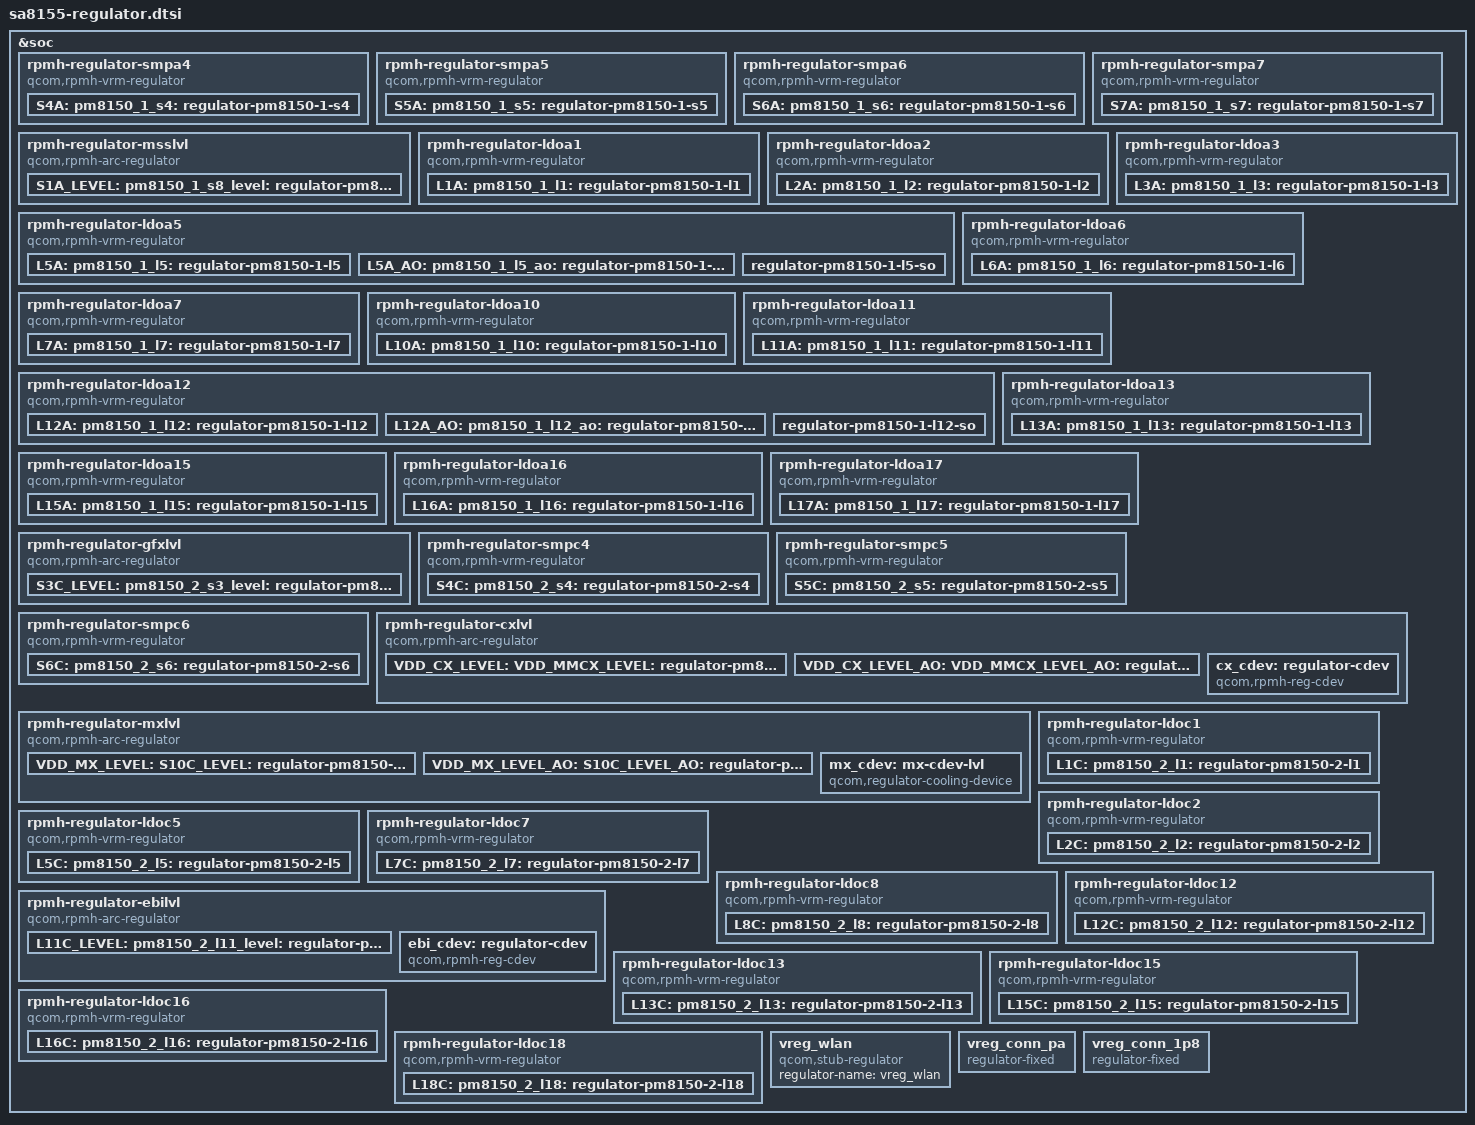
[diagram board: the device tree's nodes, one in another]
/* Copyright (c) 2018, The Linux Foundation. All rights reserved.
 *
 * This program is free software; you can redistribute it and/or modify
 * it under the terms of the GNU General Public License version 2 and
 * only version 2 as published by the Free Software Foundation.
 *
 * This program is distributed in the hope that it will be useful,
 * but WITHOUT ANY WARRANTY; without even the implied warranty of
 * MERCHANTABILITY or FITNESS FOR A PARTICULAR PURPOSE.  See the
 * GNU General Public License for more details.
 */

#include <dt-bindings/regulator/qcom,rpmh-regulator.h>

&soc {
	/* RPMh regulators: */

	rpmh-regulator-smpa4 {
		compatible = "qcom,rpmh-vrm-regulator";
		mboxes = <&apps_rsc 0>;
		qcom,resource-name = "smpa4";
		S4A: pm8150_1_s4: regulator-pm8150-1-s4 {
			regulator-name = "pm8150_1_s4";
			qcom,set = <RPMH_REGULATOR_SET_ALL>;
			regulator-min-microvolt = <1800000>;
			regulator-max-microvolt = <1800000>;
			qcom,init-voltage = <1800000>;
		};
	};

	rpmh-regulator-smpa5 {
		compatible = "qcom,rpmh-vrm-regulator";
		mboxes = <&apps_rsc 0>;
		qcom,resource-name = "smpa5";
		S5A: pm8150_1_s5: regulator-pm8150-1-s5 {
			regulator-name = "pm8150_1_s5";
			qcom,set = <RPMH_REGULATOR_SET_ALL>;
			regulator-min-microvolt = <1824000>;
			regulator-max-microvolt = <2040000>;
			qcom,init-voltage = <1824000>;
		};
	};

	rpmh-regulator-smpa6 {
		compatible = "qcom,rpmh-vrm-regulator";
		mboxes = <&apps_rsc 0>;
		qcom,resource-name = "smpa6";
		S6A: pm8150_1_s6: regulator-pm8150-1-s6 {
			regulator-name = "pm8150_1_s6";
			qcom,set = <RPMH_REGULATOR_SET_ALL>;
			regulator-min-microvolt = <600000>;
			regulator-max-microvolt = <1352000>;
			qcom,init-voltage = <600000>;
		};
	};

	rpmh-regulator-smpa7 {
		compatible = "qcom,rpmh-vrm-regulator";
		mboxes = <&apps_rsc 0>;
		qcom,resource-name = "smpa7";
		S7A: pm8150_1_s7: regulator-pm8150-1-s7 {
			regulator-name = "pm8150_1_s7";
			qcom,set = <RPMH_REGULATOR_SET_ALL>;
			regulator-min-microvolt = <600000>;
			regulator-max-microvolt = <600000>;
			qcom,init-voltage = <600000>;
		};
	};

	/* PM8150_1 S8 = VDD_MODEM supply */
	rpmh-regulator-msslvl {
		compatible = "qcom,rpmh-arc-regulator";
		mboxes = <&apps_rsc 0>;
		qcom,resource-name = "mss.lvl";
		S1A_LEVEL: pm8150_1_s8_level: regulator-pm8150-1-s8-level {
			regulator-name = "pm8150_1_s8_level";
			qcom,set = <RPMH_REGULATOR_SET_ALL>;
			regulator-min-microvolt
				= <RPMH_REGULATOR_LEVEL_RETENTION>;
			regulator-max-microvolt
				= <RPMH_REGULATOR_LEVEL_MAX>;
			qcom,init-voltage-level
				= <RPMH_REGULATOR_LEVEL_RETENTION>;
		};
	};

	rpmh-regulator-ldoa1 {
		compatible = "qcom,rpmh-vrm-regulator";
		mboxes = <&apps_rsc 0>;
		qcom,resource-name = "ldoa1";
		qcom,regulator-type = "pmic5-ldo";
		qcom,supported-modes =
			<RPMH_REGULATOR_MODE_LPM
			 RPMH_REGULATOR_MODE_HPM>;
		qcom,mode-threshold-currents = <0 1>;
		L1A: pm8150_1_l1: regulator-pm8150-1-l1 {
			regulator-name = "pm8150_1_l1";
			qcom,set = <RPMH_REGULATOR_SET_ALL>;
			regulator-min-microvolt = <752000>;
			regulator-max-microvolt = <752000>;
			qcom,init-voltage = <752000>;
			qcom,init-mode = <RPMH_REGULATOR_MODE_LPM>;
		};
	};

	rpmh-regulator-ldoa2 {
		compatible = "qcom,rpmh-vrm-regulator";
		mboxes = <&apps_rsc 0>;
		qcom,resource-name = "ldoa2";
		qcom,regulator-type = "pmic5-ldo";
		qcom,supported-modes =
			<RPMH_REGULATOR_MODE_LPM
			 RPMH_REGULATOR_MODE_HPM>;
		qcom,mode-threshold-currents = <0 10000>;
		L2A: pm8150_1_l2: regulator-pm8150-1-l2 {
			regulator-name = "pm8150_1_l2";
			qcom,set = <RPMH_REGULATOR_SET_ALL>;
			regulator-min-microvolt = <3072000>;
			regulator-max-microvolt = <3072000>;
			qcom,init-voltage = <3072000>;
			qcom,init-mode = <RPMH_REGULATOR_MODE_LPM>;
		};
	};

	rpmh-regulator-ldoa3 {
		compatible = "qcom,rpmh-vrm-regulator";
		mboxes = <&apps_rsc 0>;
		qcom,resource-name = "ldoa3";
		qcom,regulator-type = "pmic5-ldo";
		qcom,supported-modes =
			<RPMH_REGULATOR_MODE_LPM
			 RPMH_REGULATOR_MODE_HPM>;
		qcom,mode-threshold-currents = <0 1>;
		L3A: pm8150_1_l3: regulator-pm8150-1-l3 {
			regulator-name = "pm8150_1_l3";
			qcom,set = <RPMH_REGULATOR_SET_ALL>;
			regulator-min-microvolt = <480000>;
			regulator-max-microvolt = <932000>;
			qcom,init-voltage = <480000>;
			qcom,init-mode = <RPMH_REGULATOR_MODE_LPM>;
		};
	};

	rpmh-regulator-ldoa5 {
		compatible = "qcom,rpmh-vrm-regulator";
		mboxes = <&apps_rsc 0>;
		qcom,resource-name = "ldoa5";
		qcom,regulator-type = "pmic5-ldo";
		qcom,supported-modes =
			<RPMH_REGULATOR_MODE_LPM
			 RPMH_REGULATOR_MODE_HPM>;
		qcom,mode-threshold-currents = <0 1>;

		L5A: pm8150_1_l5: regulator-pm8150-1-l5 {
			regulator-name = "pm8150_1_l5";
			qcom,set = <RPMH_REGULATOR_SET_ALL>;
			regulator-min-microvolt = <880000>;
			regulator-max-microvolt = <888000>;
			qcom,init-voltage = <880000>;
			qcom,init-mode = <RPMH_REGULATOR_MODE_LPM>;
		};

		L5A_AO: pm8150_1_l5_ao: regulator-pm8150-1-l5-ao {
			regulator-name = "pm8150_1_l5_ao";
			qcom,set = <RPMH_REGULATOR_SET_ACTIVE>;
			regulator-min-microvolt = <880000>;
			regulator-max-microvolt = <888000>;
			qcom,init-voltage = <880000>;
			qcom,init-mode = <RPMH_REGULATOR_MODE_LPM>;
		};

		regulator-pm8150-1-l5-so {
			regulator-name = "pm8150_1_l5_so";
			qcom,set = <RPMH_REGULATOR_SET_SLEEP>;
			regulator-min-microvolt = <880000>;
			regulator-max-microvolt = <888000>;
			qcom,init-voltage = <880000>;
			qcom,init-mode = <RPMH_REGULATOR_MODE_LPM>;
			qcom,init-enable = <0>;
		};
	};

	rpmh-regulator-ldoa6 {
		compatible = "qcom,rpmh-vrm-regulator";
		mboxes = <&apps_rsc 0>;
		qcom,resource-name = "ldoa6";
		qcom,regulator-type = "pmic5-ldo";
		qcom,supported-modes =
			<RPMH_REGULATOR_MODE_LPM
			 RPMH_REGULATOR_MODE_HPM>;
		qcom,mode-threshold-currents = <0 10000>;
		L6A: pm8150_1_l6: regulator-pm8150-1-l6 {
			regulator-name = "pm8150_1_l6";
			qcom,set = <RPMH_REGULATOR_SET_ALL>;
			regulator-min-microvolt = <1200000>;
			regulator-max-microvolt = <1200000>;
			qcom,init-voltage = <1200000>;
			qcom,init-mode = <RPMH_REGULATOR_MODE_LPM>;
		};
	};

	rpmh-regulator-ldoa7 {
		compatible = "qcom,rpmh-vrm-regulator";
		mboxes = <&apps_rsc 0>;
		qcom,resource-name = "ldoa7";
		qcom,regulator-type = "pmic5-ldo";
		qcom,supported-modes =
			<RPMH_REGULATOR_MODE_LPM
			 RPMH_REGULATOR_MODE_HPM>;
		qcom,mode-threshold-currents = <0 1>;
		L7A: pm8150_1_l7: regulator-pm8150-1-l7 {
			regulator-name = "pm8150_1_l7";
			qcom,set = <RPMH_REGULATOR_SET_ALL>;
			regulator-min-microvolt = <1800000>;
			regulator-max-microvolt = <1800000>;
			qcom,init-voltage = <1800000>;
			qcom,init-mode = <RPMH_REGULATOR_MODE_LPM>;
		};
	};

	rpmh-regulator-ldoa10 {
		compatible = "qcom,rpmh-vrm-regulator";
		mboxes = <&apps_rsc 0>;
		qcom,resource-name = "ldoa10";
		qcom,regulator-type = "pmic5-ldo";
		qcom,supported-modes =
			<RPMH_REGULATOR_MODE_LPM
			 RPMH_REGULATOR_MODE_HPM>;
		qcom,mode-threshold-currents = <0 10000>;
		L10A: pm8150_1_l10: regulator-pm8150-1-l10 {
			regulator-name = "pm8150_1_l10";
			qcom,set = <RPMH_REGULATOR_SET_ALL>;
			regulator-min-microvolt = <2504000>;
			regulator-max-microvolt = <2960000>;
			qcom,init-voltage = <2504000>;
			qcom,init-mode = <RPMH_REGULATOR_MODE_LPM>;
		};
	};

	rpmh-regulator-ldoa11 {
		compatible = "qcom,rpmh-vrm-regulator";
		mboxes = <&apps_rsc 0>;
		qcom,resource-name = "ldoa11";
		qcom,regulator-type = "pmic5-ldo";
		qcom,supported-modes =
			<RPMH_REGULATOR_MODE_LPM
			 RPMH_REGULATOR_MODE_HPM>;
		qcom,mode-threshold-currents = <0 1>;
		L11A: pm8150_1_l11: regulator-pm8150-1-l11 {
			regulator-name = "pm8150_1_l11";
			qcom,set = <RPMH_REGULATOR_SET_ALL>;
			regulator-min-microvolt = <800000>;
			regulator-max-microvolt = <800000>;
			qcom,init-voltage = <800000>;
			qcom,init-mode = <RPMH_REGULATOR_MODE_LPM>;
		};
	};

	rpmh-regulator-ldoa12 {
		compatible = "qcom,rpmh-vrm-regulator";
		mboxes = <&apps_rsc 0>;
		qcom,resource-name = "ldoa12";
		qcom,regulator-type = "pmic5-ldo";
		qcom,supported-modes =
			<RPMH_REGULATOR_MODE_LPM
			 RPMH_REGULATOR_MODE_HPM>;
		qcom,mode-threshold-currents = <0 1>;
		L12A: pm8150_1_l12: regulator-pm8150-1-l12 {
			regulator-name = "pm8150_1_l12";
			qcom,set = <RPMH_REGULATOR_SET_ALL>;
			regulator-min-microvolt = <1800000>;
			regulator-max-microvolt = <1800000>;
			qcom,init-voltage = <1800000>;
			qcom,init-mode = <RPMH_REGULATOR_MODE_LPM>;
		};

		L12A_AO: pm8150_1_l12_ao: regulator-pm8150-1-l12-ao {
			regulator-name = "pm8150_1_l12_ao";
			qcom,set = <RPMH_REGULATOR_SET_ACTIVE>;
			regulator-min-microvolt = <1800000>;
			regulator-max-microvolt = <1800000>;
			qcom,init-voltage = <1800000>;
			qcom,init-mode = <RPMH_REGULATOR_MODE_LPM>;
		};

		regulator-pm8150-1-l12-so {
			regulator-name = "pm8150_1_l12_so";
			qcom,set = <RPMH_REGULATOR_SET_SLEEP>;
			regulator-min-microvolt = <1800000>;
			regulator-max-microvolt = <1800000>;
			qcom,init-voltage = <1800000>;
			qcom,init-mode = <RPMH_REGULATOR_MODE_LPM>;
			qcom,init-enable = <0>;
		};
	};

	rpmh-regulator-ldoa13 {
		compatible = "qcom,rpmh-vrm-regulator";
		mboxes = <&apps_rsc 0>;
		qcom,resource-name = "ldoa13";
		qcom,regulator-type = "pmic5-ldo";
		qcom,supported-modes =
			<RPMH_REGULATOR_MODE_LPM
			 RPMH_REGULATOR_MODE_HPM>;
		qcom,mode-threshold-currents = <0 1>;
		L13A: pm8150_1_l13: regulator-pm8150-1-l13 {
			regulator-name = "pm8150_1_l13";
			qcom,set = <RPMH_REGULATOR_SET_ALL>;
			regulator-min-microvolt = <2704000>;
			regulator-max-microvolt = <2704000>;
			qcom,init-voltage = <2704000>;
			qcom,init-mode = <RPMH_REGULATOR_MODE_LPM>;
		};
	};

	rpmh-regulator-ldoa15 {
		compatible = "qcom,rpmh-vrm-regulator";
		mboxes = <&apps_rsc 0>;
		qcom,resource-name = "ldoa15";
		qcom,regulator-type = "pmic5-ldo";
		qcom,supported-modes =
			<RPMH_REGULATOR_MODE_LPM
			 RPMH_REGULATOR_MODE_HPM>;
		qcom,mode-threshold-currents = <0 1>;
		L15A: pm8150_1_l15: regulator-pm8150-1-l15 {
			regulator-name = "pm8150_1_l15";
			qcom,set = <RPMH_REGULATOR_SET_ALL>;
			regulator-min-microvolt = <1704000>;
			regulator-max-microvolt = <1704000>;
			qcom,init-voltage = <1704000>;
			qcom,init-mode = <RPMH_REGULATOR_MODE_LPM>;
		};
	};

	rpmh-regulator-ldoa16 {
		compatible = "qcom,rpmh-vrm-regulator";
		mboxes = <&apps_rsc 0>;
		qcom,resource-name = "ldoa16";
		qcom,regulator-type = "pmic5-ldo";
		qcom,supported-modes =
			<RPMH_REGULATOR_MODE_LPM
			 RPMH_REGULATOR_MODE_HPM>;
		qcom,mode-threshold-currents = <0 1>;
		L16A: pm8150_1_l16: regulator-pm8150-1-l16 {
			regulator-name = "pm8150_1_l16";
			qcom,set = <RPMH_REGULATOR_SET_ALL>;
			regulator-min-microvolt = <2704000>;
			regulator-max-microvolt = <2960000>;
			qcom,init-voltage = <2704000>;
			qcom,init-mode = <RPMH_REGULATOR_MODE_LPM>;
		};
	};

	rpmh-regulator-ldoa17 {
		compatible = "qcom,rpmh-vrm-regulator";
		mboxes = <&apps_rsc 0>;
		qcom,resource-name = "ldoa17";
		qcom,regulator-type = "pmic5-ldo";
		qcom,supported-modes =
			<RPMH_REGULATOR_MODE_LPM
			 RPMH_REGULATOR_MODE_HPM>;
		qcom,mode-threshold-currents = <0 1>;
		L17A: pm8150_1_l17: regulator-pm8150-1-l17 {
			regulator-name = "pm8150_1_l17";
			qcom,set = <RPMH_REGULATOR_SET_ALL>;
			regulator-min-microvolt = <2704000>;
			regulator-max-microvolt = <2960000>;
			qcom,init-voltage = <2704000>;
			qcom,init-mode = <RPMH_REGULATOR_MODE_LPM>;
		};
	};

	/* PM8150_2 S3 + S2 + S1 = 3 phase VDD_GFX supply */
	rpmh-regulator-gfxlvl {
		compatible = "qcom,rpmh-arc-regulator";
		mboxes = <&apps_rsc 0>;
		qcom,resource-name = "gfx.lvl";
		S3C_LEVEL: pm8150_2_s3_level: regulator-pm8150-2-s3-level {
			regulator-name = "pm8150_2_s3_level";
			qcom,set = <RPMH_REGULATOR_SET_ALL>;
			regulator-min-microvolt
				= <RPMH_REGULATOR_LEVEL_RETENTION>;
			regulator-max-microvolt
				= <RPMH_REGULATOR_LEVEL_MAX>;
			qcom,init-voltage-level
				= <RPMH_REGULATOR_LEVEL_RETENTION>;
		};
	};

	rpmh-regulator-smpc4 {
		compatible = "qcom,rpmh-vrm-regulator";
		mboxes = <&apps_rsc 0>;
		qcom,resource-name = "smpc4";
		S4C: pm8150_2_s4: regulator-pm8150-2-s4 {
			regulator-name = "pm8150_2_s4";
			qcom,set = <RPMH_REGULATOR_SET_ALL>;
			regulator-min-microvolt = <800000>;
			regulator-max-microvolt = <1400000>;
			qcom,init-voltage = <800000>;
		};
	};

	rpmh-regulator-smpc5 {
		compatible = "qcom,rpmh-vrm-regulator";
		mboxes = <&apps_rsc 0>;
		qcom,resource-name = "smpc5";
		S5C: pm8150_2_s5: regulator-pm8150-2-s5 {
			regulator-name = "pm8150_2_s5";
			qcom,set = <RPMH_REGULATOR_SET_ALL>;
			regulator-min-microvolt = <1824000>;
			regulator-max-microvolt = <2040000>;
			qcom,init-voltage = <1824000>;
		};
	};

	rpmh-regulator-smpc6 {
		compatible = "qcom,rpmh-vrm-regulator";
		mboxes = <&apps_rsc 0>;
		qcom,resource-name = "smpc6";
		S6C: pm8150_2_s6: regulator-pm8150-2-s6 {
			regulator-name = "pm8150_2_s6";
			qcom,set = <RPMH_REGULATOR_SET_ALL>;
			regulator-min-microvolt = <1128000>;
			regulator-max-microvolt = <1128000>;
			qcom,init-voltage = <1128000>;
		};
	};

	/* PM8150_2 S9 + S8 + S7 = VDD_CX supply */
	rpmh-regulator-cxlvl {
		compatible = "qcom,rpmh-arc-regulator";
		mboxes = <&apps_rsc 0>;
		qcom,resource-name = "cx.lvl";
		pm8150_2_s9_level-parent-supply = <&VDD_MX_LEVEL>;
		pm8150_2_s9_level_ao-parent-supply = <&VDD_MX_LEVEL_AO>;

		VDD_CX_LEVEL: VDD_MMCX_LEVEL:
		S9C_LEVEL: pm8150_2_s9_level: regulator-pm8150-2-s9-level {
			regulator-name = "pm8150_2_s9_level";
			qcom,set = <RPMH_REGULATOR_SET_ALL>;
			regulator-min-microvolt
				= <RPMH_REGULATOR_LEVEL_RETENTION>;
			regulator-max-microvolt
				= <RPMH_REGULATOR_LEVEL_MAX>;
			qcom,init-voltage-level
				= <RPMH_REGULATOR_LEVEL_RETENTION>;
			qcom,min-dropout-voltage-level = <(-1)>;
		};

		VDD_CX_LEVEL_AO: VDD_MMCX_LEVEL_AO: S9C_LEVEL_AO:
		pm8150_2_s9_level_ao: regulator-pm8150-2-s9-level-ao {
			regulator-name = "pm8150_2_s9_level_ao";
			qcom,set = <RPMH_REGULATOR_SET_ACTIVE>;
			regulator-min-microvolt
				= <RPMH_REGULATOR_LEVEL_RETENTION>;
			regulator-max-microvolt
				= <RPMH_REGULATOR_LEVEL_MAX>;
			qcom,init-voltage-level
				= <RPMH_REGULATOR_LEVEL_RETENTION>;
			qcom,min-dropout-voltage-level = <(-1)>;
		};

		cx_cdev: regulator-cdev {
			compatible = "qcom,rpmh-reg-cdev";
			mboxes = <&qmp_aop 0>;
			qcom,reg-resource-name = "cx";
			#cooling-cells = <2>;
		};
	};

	/* PM8150_2 S10 = VDD_MX supply */
	rpmh-regulator-mxlvl {
		compatible = "qcom,rpmh-arc-regulator";
		mboxes = <&apps_rsc 0>;
		qcom,resource-name = "mx.lvl";

		VDD_MX_LEVEL:
		S10C_LEVEL: pm8150_2_s10_level: regulator-pm8150-2-s10-level {
			regulator-name = "pm8150_2_s10_level";
			qcom,set = <RPMH_REGULATOR_SET_ALL>;
			regulator-min-microvolt
				= <RPMH_REGULATOR_LEVEL_RETENTION>;
			regulator-max-microvolt
				= <RPMH_REGULATOR_LEVEL_MAX>;
			qcom,init-voltage-level
				= <RPMH_REGULATOR_LEVEL_RETENTION>;
		};

		VDD_MX_LEVEL_AO: S10C_LEVEL_AO:
		pm8150_2_s10_level_ao: regulator-pm8150-2-s10-level-ao {
			regulator-name = "pm8150_2_s10_level_ao";
			qcom,set = <RPMH_REGULATOR_SET_ACTIVE>;
			regulator-min-microvolt
				= <RPMH_REGULATOR_LEVEL_RETENTION>;
			regulator-max-microvolt
				= <RPMH_REGULATOR_LEVEL_MAX>;
			qcom,init-voltage-level
				= <RPMH_REGULATOR_LEVEL_RETENTION>;
		};

		mx_cdev: mx-cdev-lvl {
			compatible = "qcom,regulator-cooling-device";
			regulator-cdev-supply = <&VDD_MX_LEVEL>;
			regulator-levels = <RPMH_REGULATOR_LEVEL_NOM
					RPMH_REGULATOR_LEVEL_OFF>;
			#cooling-cells = <2>;
		};
	};

	rpmh-regulator-ldoc1 {
		compatible = "qcom,rpmh-vrm-regulator";
		mboxes = <&apps_rsc 0>;
		qcom,resource-name = "ldoc1";
		qcom,regulator-type = "pmic5-ldo";
		qcom,supported-modes =
			<RPMH_REGULATOR_MODE_LPM
			 RPMH_REGULATOR_MODE_HPM>;
		qcom,mode-threshold-currents = <0 1>;
		L1C: pm8150_2_l1: regulator-pm8150-2-l1 {
			regulator-name = "pm8150_2_l1";
			qcom,set = <RPMH_REGULATOR_SET_ALL>;
			regulator-min-microvolt = <1304000>;
			regulator-max-microvolt = <1304000>;
			qcom,init-voltage = <1304000>;
			qcom,init-mode = <RPMH_REGULATOR_MODE_LPM>;
		};
	};

	rpmh-regulator-ldoc2 {
		compatible = "qcom,rpmh-vrm-regulator";
		mboxes = <&apps_rsc 0>;
		qcom,resource-name = "ldoc2";
		qcom,regulator-type = "pmic5-ldo";
		qcom,supported-modes =
			<RPMH_REGULATOR_MODE_LPM
			 RPMH_REGULATOR_MODE_HPM>;
		qcom,mode-threshold-currents = <0 1>;
		L2C: pm8150_2_l2: regulator-pm8150-2-l2 {
			regulator-name = "pm8150_2_l2";
			qcom,set = <RPMH_REGULATOR_SET_ALL>;
			regulator-min-microvolt = <1704000>;
			regulator-max-microvolt = <2928000>;
			qcom,init-voltage = <1704000>;
			qcom,init-mode = <RPMH_REGULATOR_MODE_LPM>;
		};
	};

	rpmh-regulator-ldoc5 {
		compatible = "qcom,rpmh-vrm-regulator";
		mboxes = <&apps_rsc 0>;
		qcom,resource-name = "ldoc5";
		qcom,regulator-type = "pmic5-ldo";
		qcom,supported-modes =
			<RPMH_REGULATOR_MODE_LPM
			 RPMH_REGULATOR_MODE_HPM>;
		qcom,mode-threshold-currents = <0 1>;
		L5C: pm8150_2_l5: regulator-pm8150-2-l5 {
			regulator-name = "pm8150_2_l5";
			qcom,set = <RPMH_REGULATOR_SET_ALL>;
			regulator-min-microvolt = <1200000>;
			regulator-max-microvolt = <1200000>;
			qcom,init-voltage = <1200000>;
			qcom,init-mode = <RPMH_REGULATOR_MODE_LPM>;
		};
	};

	rpmh-regulator-ldoc7 {
		compatible = "qcom,rpmh-vrm-regulator";
		mboxes = <&apps_rsc 0>;
		qcom,resource-name = "ldoc7";
		qcom,regulator-type = "pmic5-ldo";
		qcom,supported-modes =
			<RPMH_REGULATOR_MODE_LPM
			 RPMH_REGULATOR_MODE_HPM>;
		qcom,mode-threshold-currents = <0 1>;
		L7C: pm8150_2_l7: regulator-pm8150-2-l7 {
			regulator-name = "pm8150_2_l7";
			qcom,set = <RPMH_REGULATOR_SET_ALL>;
			regulator-min-microvolt = <1800000>;
			regulator-max-microvolt = <1800000>;
			qcom,init-voltage = <1800000>;
			qcom,init-mode = <RPMH_REGULATOR_MODE_LPM>;
		};
	};

	rpmh-regulator-ldoc8 {
		compatible = "qcom,rpmh-vrm-regulator";
		mboxes = <&apps_rsc 0>;
		qcom,resource-name = "ldoc8";
		qcom,regulator-type = "pmic5-ldo";
		qcom,supported-modes =
			<RPMH_REGULATOR_MODE_LPM
			 RPMH_REGULATOR_MODE_HPM>;
		qcom,mode-threshold-currents = <0 1>;
		L8C: pm8150_2_l8: regulator-pm8150-2-l8 {
			regulator-name = "pm8150_2_l8";
			qcom,set = <RPMH_REGULATOR_SET_ALL>;
			regulator-min-microvolt = <1200000>;
			regulator-max-microvolt = <1200000>;
			qcom,init-voltage = <1200000>;
			qcom,init-mode = <RPMH_REGULATOR_MODE_LPM>;
		};
	};

	/* PM8150_2 L11 = VDD_EBI supply */
	rpmh-regulator-ebilvl {
		compatible = "qcom,rpmh-arc-regulator";
		mboxes = <&apps_rsc 0>;
		qcom,resource-name = "ebi.lvl";
		L11C_LEVEL: pm8150_2_l11_level: regulator-pm8150-2-l11-level {
			regulator-name = "pm8150_2_l11_level";
			qcom,set = <RPMH_REGULATOR_SET_ALL>;
			regulator-min-microvolt
				= <RPMH_REGULATOR_LEVEL_RETENTION>;
			regulator-max-microvolt
				= <RPMH_REGULATOR_LEVEL_MAX>;
			qcom,init-voltage-level
				= <RPMH_REGULATOR_LEVEL_RETENTION>;
		};

		ebi_cdev: regulator-cdev {
			compatible = "qcom,rpmh-reg-cdev";
			mboxes = <&qmp_aop 0>;
			qcom,reg-resource-name = "ebi";
			#cooling-cells = <2>;
		};
	};

	rpmh-regulator-ldoc12 {
		compatible = "qcom,rpmh-vrm-regulator";
		mboxes = <&apps_rsc 0>;
		qcom,resource-name = "ldoc12";
		qcom,regulator-type = "pmic5-ldo";
		qcom,supported-modes =
			<RPMH_REGULATOR_MODE_LPM
			 RPMH_REGULATOR_MODE_HPM>;
		qcom,mode-threshold-currents = <0 1>;
		L12C: pm8150_2_l12: regulator-pm8150-2-l12 {
			regulator-name = "pm8150_2_l12";
			qcom,set = <RPMH_REGULATOR_SET_ALL>;
			regulator-min-microvolt = <1704000>;
			regulator-max-microvolt = <1888000>;
			qcom,init-voltage = <1704000>;
			qcom,init-mode = <RPMH_REGULATOR_MODE_LPM>;
		};
	};

	rpmh-regulator-ldoc13 {
		compatible = "qcom,rpmh-vrm-regulator";
		mboxes = <&apps_rsc 0>;
		qcom,resource-name = "ldoc13";
		qcom,regulator-type = "pmic5-ldo";
		qcom,supported-modes =
			<RPMH_REGULATOR_MODE_LPM
			 RPMH_REGULATOR_MODE_HPM>;
		qcom,mode-threshold-currents = <0 1>;
		L13C: pm8150_2_l13: regulator-pm8150-2-l13 {
			regulator-name = "pm8150_2_l13";
			qcom,set = <RPMH_REGULATOR_SET_ALL>;
			regulator-min-microvolt = <1800000>;
			regulator-max-microvolt = <2960000>;
			qcom,init-voltage = <1800000>;
			qcom,init-mode = <RPMH_REGULATOR_MODE_LPM>;
		};
	};

	rpmh-regulator-ldoc15 {
		compatible = "qcom,rpmh-vrm-regulator";
		mboxes = <&apps_rsc 0>;
		qcom,resource-name = "ldoc15";
		qcom,regulator-type = "pmic5-ldo";
		qcom,supported-modes =
			<RPMH_REGULATOR_MODE_LPM
			 RPMH_REGULATOR_MODE_HPM>;
		qcom,mode-threshold-currents = <0 1>;
		L15C: pm8150_2_l15: regulator-pm8150-2-l15 {
			regulator-name = "pm8150_2_l15";
			qcom,set = <RPMH_REGULATOR_SET_ALL>;
			regulator-min-microvolt = <1800000>;
			regulator-max-microvolt = <1904000>;
			qcom,init-voltage = <1800000>;
			qcom,init-mode = <RPMH_REGULATOR_MODE_LPM>;
		};
	};

	rpmh-regulator-ldoc16 {
		compatible = "qcom,rpmh-vrm-regulator";
		mboxes = <&apps_rsc 0>;
		qcom,resource-name = "ldoc16";
		qcom,regulator-type = "pmic5-ldo";
		qcom,supported-modes =
			<RPMH_REGULATOR_MODE_LPM
			 RPMH_REGULATOR_MODE_HPM>;
		qcom,mode-threshold-currents = <0 1>;
		L16C: pm8150_2_l16: regulator-pm8150-2-l16 {
			regulator-name = "pm8150_2_l16";
			qcom,set = <RPMH_REGULATOR_SET_ALL>;
			regulator-min-microvolt = <2704000>;
			regulator-max-microvolt = <3008000>;
			qcom,init-voltage = <2704000>;
			qcom,init-mode = <RPMH_REGULATOR_MODE_LPM>;
		};
	};

	rpmh-regulator-ldoc18 {
		compatible = "qcom,rpmh-vrm-regulator";
		mboxes = <&apps_rsc 0>;
		qcom,resource-name = "ldoc18";
		qcom,regulator-type = "pmic5-ldo";
		qcom,supported-modes =
			<RPMH_REGULATOR_MODE_LPM
			 RPMH_REGULATOR_MODE_HPM>;
		qcom,mode-threshold-currents = <0 1>;
		proxy-supply = <&pm8150_2_l18>;
		L18C: pm8150_2_l18: regulator-pm8150-2-l18 {
			regulator-name = "pm8150_2_l18";
			qcom,set = <RPMH_REGULATOR_SET_ALL>;
			regulator-min-microvolt = <880000>;
			regulator-max-microvolt = <880000>;
			qcom,proxy-consumer-enable;
			qcom,proxy-consumer-current = <23800>;
			qcom,init-voltage = <880000>;
			qcom,init-mode = <RPMH_REGULATOR_MODE_LPM>;
		};
	};

	/* Rome 3.3V supply */
	vreg_wlan: vreg_wlan {
		compatible = "qcom,stub-regulator";
		regulator-name = "vreg_wlan";
	};

	/* PWR_CTR1_VDD_PA supply */
	vreg_conn_pa: vreg_conn_pa {
		compatible = "regulator-fixed";
		regulator-name = "vreg_conn_pa";
		pinctrl-names = "default";
		pinctrl-0 = <&conn_power_pa_active>;
		startup-delay-us = <4000>;
		enable-active-high;
		gpio = <&tlmm 173 0>;
	};

	/* PWR_CTR2_VDD_1P8 supply */
	vreg_conn_1p8: vreg_conn_1p8 {
		compatible = "regulator-fixed";
		regulator-name = "vreg_conn_1p8";
		pinctrl-names = "default";
		pinctrl-0 = <&conn_power_1p8_active>;
		startup-delay-us = <4000>;
		enable-active-high;
		gpio = <&tlmm 174 0>;
	};
};
